# CC2340R5 register map
File version: 1.0
CPU: CM0P 1.0, other endian, MPU, FPU, 3 interrupt priority bits
Registers are 32-bit, read-write, reset 0x0 unless marked. A register's access mark holds for its fields unless they carry their own. Offsets are from the block's base; [hi:lo] are bit positions; {n}, {i} and the like mark numbered series; 'fields as' and 'values as' point back to an identical list.

## AES — The AES-128 crypto peripheral accellerates AES-128 block cipher encryption (ECB). The peripheral does also offer hardware features to accellerate cipher modes implemented in software: * CBC-MAC * CBC * CTR * CFB * OFB * PCBC The module provides two data registers that can be input to ECB encryption. These are termed TXT and BUF. TXT is the AES-128 work buffer, and content changes during an ECB encryption. Software cannot update TXT during encryption. BUF is an auxiliary 128-bit buffer with multiple purposes: * initialization vector(IV) storage * counter in CTR cipher mode * hold next value of TXT Software can update BUF during an ECB enryption. This allows software to write next TXT during an encryption an hence save ECB idle times.
Base 0x400C0000
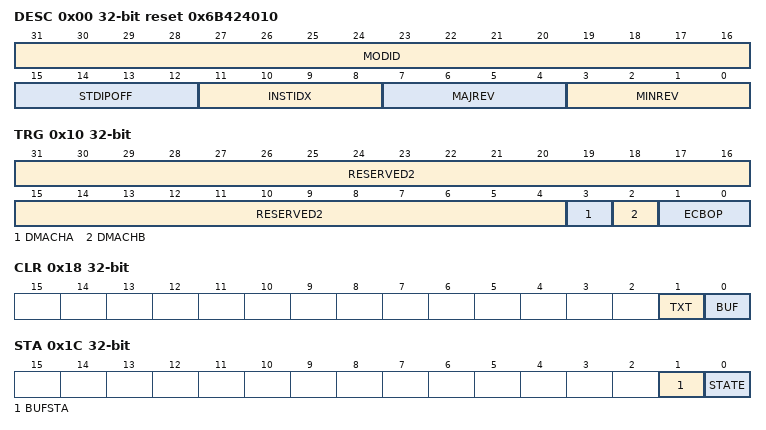
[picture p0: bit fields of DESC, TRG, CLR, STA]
0x00 DESC reset 0x6B424010 — Description Register. This register provides IP module ID, revision information, instance index and standard MMR registers offset.
  [31:16] MODID ro — [31:16] Module identifier used to uniquely identify this IP
  [15:12] STDIPOFF ro — [15:12] Standard IP MMR block offset. Standard IP MMRs are the set of from aggregated IRQ registers till DTB. 0: Standard IP MMRs do not exist 0x1-0xF: Standard IP MMRs begin at offset of (64*STDIPOFF from the base IP address)
  [11:8] INSTIDX ro — [11:8] IP Instance ID number. If multiple instances of IP exist in the device, this field can identify the instance number (0-15).
  [7:4] MAJREV ro — [7:4] Major revision of IP (0-15).
  [3:0] MINREV ro — [3:0] Minor Revision of IP(0-15).
0x10 TRG — Trigger Use this register to manually trigger operations.
  [31:4] RESERVED2 wo — [31:4] Reads to this field return zero, writes to this field are ignored.
  [3] DMACHA wo — [3:3] Write 1 to this field to manually trigger channel A request.
  [2] DMACHB wo — [2:2] Write 1 to this field to manually trigger channel B request.
  [1:0] ECBOP wo — [1:0] Electronic Codebook (ECB) Operation Write an enumerated value to this field when STA.STATE = IDLE to manually trigger an ECB encryption. If condition is not met, the trigger is ignored. Non-enumerated values are ignored. Enumerated value indicates source of ECB operation
    3=TXTXBUF (TXT = ECB(KEY, TXT XOR BUF)); 2=BUF (TXT = ECB(KEY,BUF)); 1=TXT (TXT = ECB(KEY,TXT))
0x14 ABORT — Abort Use this register to abort current ECB encryption.
  [0] ECB wo — [0:0] Electronic Codebook Write 1 to this field to abort an ongoing ECB encryption. An abort will clear TXT, BUF, DMA, AUTOCFG registers
0x18 CLR — Clear Use this register to clear contents of TXT and BUF when STA.STATE = IDLE. If condition is not met, the contents remain unchanged.
  [1] TXT wo — [1:1] Write 1 to this field to clear TXT.
  [0] BUF wo — [0:0] Write 1 to this field to clear BUF.
0x1C STA — Status This register provides information on ECB accellerator state and BUF status.
  [1] BUFSTA ro — [1:1] BUF Status Field gives the status of BUF, indicating EMPTY or FULL, when AUTOCFG.TRGECB = WRBUF3. If AUTOCFG.TRGECB != WRBUF3, then STA.BUFSTA will hold the value 0. Note : Useful for CBC-MAC
    1=FULL (Data stored in BUF is not yet consumed by the AES engine. Next block of data cannot be written into BUF until STA.STATE = IDLE.); 0=EMPTY (Data stored in BUF is already consumed by the AES engine and next block of data can be written in BUF)
  [0] STATE ro — [0:0] State Field gives the state of the ECB encryption engine.
    1=BUSY (ECB encryption active.); 0=IDLE (ECB is IDLE.)
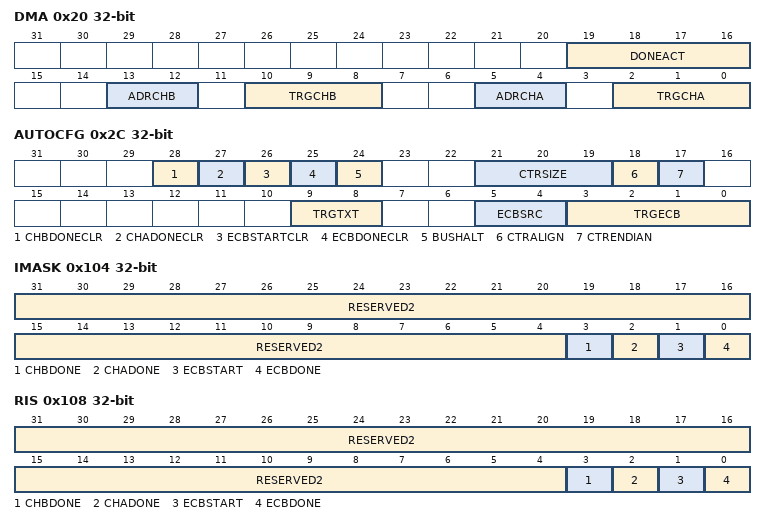
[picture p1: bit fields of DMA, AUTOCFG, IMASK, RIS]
0x20 DMA — Direct Memory Access This register controls the conditions that will generate burst requests on each DMA channel.
  [19:16] DONEACT — [19:16] Done Action This field determines the side effects of DMA done. It is allowed to configure this field with an OR-combination of supported enums, with the exception that GATE_TRGECB_ON_CHA and GATE_TRGECB_ON_CHA_DEL shall be mutually exclusive
    8=CLR_TXT_ON_CHB (DMA channel B done event clears TXT0 thru TXT3 if STA.STATE = IDLE. Event is ignored if condition is not met.); 4=CLR_TXT_ON_CHA (DMA channel A done event clears TXT0 thru TXT3 if STA.STATE = IDLE. Event is ignored if condition is not met.); 2=GATE_TRGECB_ON_CHA_DEL (Due to the pipelining of BUF writes, in certain modes, DMA CHA Done appears before the last but one ECB has completed. Setting this bit, will gate the triggers defined in AUTOCFG.TRGECB only after the last write by CHA is consumed by AES FSM. Used in ECB,CBC,CBC-MAC modes (having multiple blocks encryption) to avoid spurious ECB triggered on last read by CHB. For single mode encryption, DMA.GATE_TRGECB_ON_CHA should be used.); 1=GATE_TRGECB_ON_CHA (Triggers defined in AUTOCFG.TRGECB are gated when RIS.CHADONE = SET.); 0=DIS (DMA done has no side effect.)
  [13:12] ADRCHB — [13:12] Channel B Read Write Address The DMA accesses DMACHB to read or write contents of TXT and BUF as a response to a burst request. This field specifes the start address of the first DMA transfer that follows the burst request. The internal address gets incremented automatically for subsequent accesses. The DMA shall transfer 8-bit, 16-bit, or 32-bit words, and shall always complete a 16-byte transfer before re-arbitration.
    3=TXTXBUF0 (Start address is TXTXBUF0.); 2=BUF0 (Start address is BUF0.); 1=TXTX0 (Start address is TXTX0.); 0=TXT0 (Start address is TXT0.)
  [10:8] TRGCHB — [10:8] Channel B Trigger Select the condition that triggers DMA channel B request. Non-enumerated values are not supported and ignored.
    4=RDTXT3 (Reads of TXT3, or TXTXBUF3 trigger request.); 3=WRTXT3 (Writes to TXT3, TXTX3, or TXTXBUF3 trigger request.); 2=ECBDONE (Completion of ECB encryption triggers request.); 1=ECBSTART (Start of ECB encryption triggers request.); 0=DIS (DMA requests are disabled.)
  [5:4] ADRCHA — [5:4] Channel A Read Write Address The DMA accesses DMACHA to read or write contents of TXT and BUF as a response to a burst request. This field specifes the start address of the first DMA transfer that follows the burst request. The internal address gets incremented automatically for subsequent accesses. The DMA shall transfer 8-bit, 16-bit, or 32-bit words, and shall always complete a 16-byte transfer before re-arbitration.
    values as ADRCHB
  [2:0] TRGCHA — [2:0] Channel A Trigger Select the condition that triggers DMA channel A request. Non-enumerated values are not supported and ignored.
    4=RDTXT3 (Reads of TXT3 or TXTXBUF3 trigger request.); 3=WRTXT3 (Writes to TXT3 or TXTX3 trigger request.); 2=ECBDONE (Completion of ECB encryption triggers request.); 1=ECBSTART (Start of ECB encryption triggers request.); 0=DIS (DMA requests are disabled.)
0x24 DMACHA — DMA Channel A data transfer DMA accesses this register to read or write contents from sequential addresses specifed by DMA.ADRCHA.
  [31:0] VAL — [31:0] Value transferred through DMA Channel A
0x28 DMACHB — DMA Channel B data transfer DMA accesses this register to read or write contents from sequential addresses specifed by DMA.ADRCHB.
  [31:0] VAL — [31:0] Value transferred through DMA Channel B
0x2C AUTOCFG — Automatic Configuration This register configures automatic hardware updates to TXT and BUF. Configure this register to reduce software overhead during cipher modes.
  [28] CHBDONECLR — [28:28] This field enable auto-clear of RIS.CHBDONE interrupt on read/write of TXT3/BUF3/TXTX3/TXTXBUF3 .
    1=EN (Enable auto-clear of RIS.CHBDONE interrupt); 0=DIS (Disable auto-clear of RIS.CHBDONE interrupt)
  [27] CHADONECLR — [27:27] This field enables auto-clear of RIS.CHADONE interrupt on read/write of TXT3/BUF3/TXTX3/TXTXBUF3 .
    1=EN (Enable auto-clear of RIS.CHADONE interrupt); 0=DIS (Disable auto-clear of RIS.CHADONE interrupt)
  [26] ECBSTARTCLR — [26:26] This field enables auto-clear of RIS.ECBSTART interrupt on read/write of TXT3/BUF3/TXTX3/TXTXBUF3 .
    1=EN (Enable auto-clear of RIS.ECBSTART interrupt); 0=DIS (Disable auto-clear of RIS.ECBSTART interrupt)
  [25] ECBDONECLR — [25:25] This field enables auto-clear of RIS.ECBDONE interrupt on read/write of TXT3/BUF3/TXTX3/TXTXBUF3 .
    1=EN (Enable auto-clear of RIS.ECBDONE interrupt); 0=DIS (Disable auto-clear of RIS.ECBDONE interrupt)
  [24] BUSHALT — [24:24] Bus Halt This field decides if bus halts on access to KEY, TXT, BUF, TXTX and TXTXBUF when STA.STATE = BUSY.
    1=EN (Enable bus halt When STA.STATE = BUSY, access to KEY, TXT, TXTX, TXTXBUF halt the bus until STA.STATE = IDLE. When STA.STATE = BUSY and if either STA.BUFSTA = FULL or AUTOCFG.CTRSIZE != DISABLE, access to BUF halts the bus until STA.STATE = IDLE.); 0=DIS (Disable bus halt When STA.STATE = BUSY, writes to KEY, TXT, TXTX are ignored, reads from TXT, TXTXBUF return zero. When STA.STATE = BUSY and if either STA.BUFSTA = FULL or AUTOCFG.CTRSIZE != DISABLE, writes to BUF are ignored, reads return zero.)
  [21:19] CTRSIZE — [21:19] Counter Size Configures size of counter as either 8,16,32,64 or 128 Non-enumerated values are not supported and ignored
    5=CTR128 (Configures counter size as 128 bit); 4=CTR64 (Configures counter size as 64 bit); 3=CTR32 (Configures counter size as 32 bit); 2=CTR16 (Configures counter size as 16 bit); 1=CTR8 (Configures counter size as 8 bit); 0=DIS (Disable CTR operation)
  [18] CTRALIGN — [18:18] Counter Alignment Specifies alignment of counter
    1=RIGHTALIGN (Indicates right aligned counter Not applicable when counter size is 128bit For 128 bit counter, all octets will be considered If right aligned, octet 8-15 will be considered based on endianness and counter size); 0=LEFTALIGN (Indicates Left Aligned Counter Not applicable for 128 bit counter size. For 128 bit counter, all octets will be considered When left aligned,,octet 0-7 will be considered , based on counter size and endianness)
  [17] CTRENDIAN — [17:17] Counter Endianness Specifies Endianness of counter
    1=BIGENDIAN (Specifies Big Endian Counter Carry will flow from octet 'n' to octet 'n-1'); 0=LITTLEENDIAN (Specifies Little Endian Counter. Carry will flow from octet 'n' to octet 'n+1')
  [9:8] TRGTXT — [9:8] Trigger for TXT This field determines if and when hardware automatically XORs BUF into TXT. Non-enumerated values are not supported and ignored. It is allowed to configure this field with an OR-combination of supported enums.
    2=RDTXTXBUF3 (Hardware XORs content of BUF into TXT upon read of TXTXBUF3.); 1=RDTXT3 (Hardware XORs content of BUF into TXT upon read of TXT3.); 0=DIS (No hardware update of TXT)
  [5:4] ECBSRC — [5:4] Electronic Codebook Source This field specifies the data source to hardware-triggered ECB encryptions. Non-enumerated values are not supported and ignored.
    values as TRG.ECBOP
  [3:0] TRGECB — [3:0] Trigger Electronic Codebook This field specifies one or more actions that indirectly trigger ECB operation It is allowed to configure this field with an OR-combination of supported enums.
    8=WRBUF3S (Write to BUF3 shall schedule to trigger single action once STA.STATE is or becomes IDLE. Subsequent writes do not trigger any action unless this setting is written again to this field.); 4=WRBUF3 (All writes to BUF3 shall be scheduled to trigger action once STA.STATE is or becomes IDLE, only when AUTOCFG.CTRSIZE = DIS.); 2=RDTXT3 (All reads of TXT3 or TXTXBUF3 trigger action, only when STA.STATE = IDLE.); 1=WRTXT3 (All writes to TXT3 or TXTX3 trigger action, only when STA.STATE = IDLE.); 0=DIS (No user action indirectly triggers ECB.)
0x50 KEY0 — Key Word 0 Write KEY0 through KEY3 to populate the 128-bit key. The key is not consumed by the hardware. It is hence not required to reload the key for subsequent block encryptions unless required by the application.
  [31:0] VAL wo — [31:0] Value of KEY[31:0].
{0x50+4i} KEY{i} (i=1..3) — Key Word {i} Write KEY0 through KEY3 to populate the 128-bit key. The key is not consumed by the hardware. It is hence not required to reload the key for subsequent block encryptions unless required by the application.
  [31:0] VAL wo — [31:0] Value of KEY[{32i+31}:{32i}]
{0x70+4i} TXT{i} (i=0..2) — Text Word {i} TXT is the 128-bit buffer, the AES-128 encryption algorithm performs its operations on. ECB input can be written to TXT, and ciphertext can be read from TXT.
  [31:0] VAL — [31:0] Value of TXT[{32i+31}:{32i}]
0x7C TXT3 — Text Word 3 TXT is the 128-bit buffer, the AES-128 encryption algorithm performs its operations on. ECB input can be written to TXT, and ciphertext can be read from TXT.
  [31:0] VAL — [31:0] Value of TXT[127:96] AUTOCFG.TRGECB decides if a write to or a read of this field triggers an encryption.
{0x80+4i} TXTX{i} (i=0..2) — Text Word {i} XOR Write data to this register to XOR data with contents in TXT{i}.VAL.
  [31:0] VAL wo — [31:0] Value in TXT{i} will be TXT{i}.VAL = VAL XOR TXT{i}.VAL
0x8C TXTX3 — Text Word 3 XOR Write data to this register to XOR data with contents in TXT3.VAL. AUTOCFG.TRGECB decides if a write to or a read of this field triggers an encryption.
  [31:0] VAL wo — [31:0] Value in TXT3 will be TXT3.VAL = VAL XOR TXT3.VAL
{0x90+4i} BUF{i} (i=0..2) — Buffer Word {i} BUF is a 128-bit auxiliary register that functions as a buffer, counter, or storage of operations in cipher modes.
  [31:0] VAL — [31:0] Value of BUF[{32i+31}:{32i}]
0x9C BUF3 — Buffer Word 3 BUF is a 128-bit auxiliary register that functions as a buffer, counter, or storage of operations in cipher modes. AUTOCFG.TRGECB decides if a write to this field triggers an encryption.
  [31:0] VAL — [31:0] Value of BUF[127:96]
{0xA0+4i} TXTXBUF{i} (i=0..2) — Text Word {i} XOR Buffer Word {i} Read this register to obtain plaintext during CFB decryption.
  [31:0] VAL ro — [31:0] Value read will be TXT{i}.VAL XOR BUF{i}.VAL
0xAC TXTXBUF3 — Text Word 3 XOR Buffer Word3 Read this register to obtain plaintext during CFB decryption.
  [31:0] VAL ro — [31:0] Value read will be TXT3.VAL XOR BUF3.VAL
0x104 IMASK — Interrupt mask. This register selects interrupt sources which are allowed to pass from RIS to MIS when the corresponding bit-fields are set to 1.
  [31:4] RESERVED2 — [31:4] Reads to this field return zero, writes to this field are ignored.
  [3] CHBDONE — [3:3] DMA Channel B Done interrupt mask
    1=EN (Enable interrupt mask); 0=DIS (Disable interrupt mask)
  [2] CHADONE — [2:2] DMA Channel A Done interrupt mask
    1=EN (Enable interrupt mask); 0=DIS (Disable interrupt mask)
  [1] ECBSTART — [1:1] ECB Start interrupt mask
    1=EN (Enable interrupt mask); 0=DIS (Disable interrupt mask)
  [0] ECBDONE — [0:0] ECB Done interrupt mask
    1=EN (Enable interrupt mask); 0=DIS (Disable interrupt mask)
0x108 RIS — Raw interrupt status. This register reflects the state of all pending interrupts, regardless of masking. This register allows the user to implement a poll scheme. A flag set in this register can be cleared by writing 1 to the corresponding ICLR register bit.
  [31:4] RESERVED2 ro — [31:4] Reads to this field return zero, writes to this field are ignored.
  [3] CHBDONE ro — [3:3] Raw interrupt status for DMA Channel B Done
    1=SET (Interrupt occurred); 0=CLR (Interrupt did not occur)
  [2] CHADONE ro — [2:2] Raw interrupt status for DMA Channel A Done
    1=SET (Interrupt occurred); 0=CLR (Interrupt did not occur)
  [1] ECBSTART ro — [1:1] Raw interrupt status for ECB Start
    1=SET (Interrupt occurred); 0=CLR (Interrupt did not occur)
  [0] ECBDONE ro — [0:0] Raw interrupt status for ECB Done
    1=SET (Interrupt occurred); 0=CLR (Interrupt did not occur)
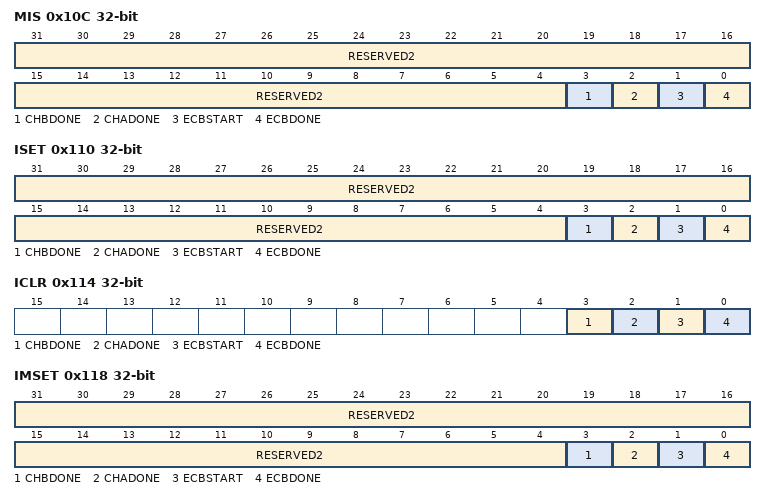
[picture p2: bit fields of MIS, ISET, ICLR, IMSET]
0x10C MIS — Masked interrupt status. This register is simply a bitwise AND of the contents of IMASK and RIS.*] registers. A flag set in this register can be cleared by writing 1 to the corresponding ICLR register bit.
  [31:4] RESERVED2 ro — [31:4] Reads to this field return zero, writes to this field are ignored.
  [3] CHBDONE ro — [3:3] Masked interrupt status for DMA Channel B Done
    1=SET (Interrupt occurred); 0=CLR (Interrupt did not occur)
  [2] CHADONE ro — [2:2] Masked interrupt status for DMA Channel A Done
    1=SET (Interrupt occurred); 0=CLR (Interrupt did not occur)
  [1] ECBSTART ro — [1:1] Masked interrupt status for ECB Start
    1=SET (Interrupt occurred); 0=CLR (Interrupt did not occur)
  [0] ECBDONE ro — [0:0] Masked interrupt status for ECB Done
    1=SET (Interrupt occurred); 0=CLR (Interrupt did not occur)
0x110 ISET — Interrupt set register. This register can used by software for diagnostics and safety checking purposes. Writing a 1 to a bit in this register will set the event and the corresponding RIS bit also gets set. If the corresponding IMASK bit is set, then the corresponding MIS register bit also gets set.
  [31:4] RESERVED2 wo — [31:4] Reads to this field return zero, writes to this field are ignored.
  [3] CHBDONE wo — [3:3] Set DMA Channel B Done interrupt
    1=SET (Set interrupt); 0=NOEFF (Writing 0 has no effect)
  [2] CHADONE wo — [2:2] Set DMA Channel A Done interrupt
    1=SET (Set interrupt); 0=NOEFF (Writing 0 has no effect)
  [1] ECBSTART wo — [1:1] Set ECB Start interrupt
    1=SET (Set interrupt); 0=NOEFF (Writing 0 has no effect)
  [0] ECBDONE wo — [0:0] Set ECB Done interrupt
    1=SET (Set interrupt); 0=NOEFF (Writing 0 has no effect)
0x114 ICLR — Interrupt clear register. This register allows software to clear interrupts. Writing a 1 to a bit in this register will clear the event and the corresponding RIS bit also gets cleared. If the corresponding IMASK bit is set, then the corresponding MIS register bit also gets cleared.
  [3] CHBDONE wo — [3:3] Clear DMA Channel B Done interrupt
    1=CLR (Clear interrupt); 0=NOEFF (Writing 0 has no effect)
  [2] CHADONE wo — [2:2] Clear DMA Channel A Done interrupt
    1=CLR (Clear interrupt); 0=NOEFF (Writing 0 has no effect)
  [1] ECBSTART wo — [1:1] Clear ECB Start interrupt
    1=CLR (Clear interrupt); 0=NOEFF (Writing 0 has no effect)
  [0] ECBDONE wo — [0:0] Clear ECB Done interrupt
    1=CLR (Clear interrupt); 0=NOEFF
0x118 IMSET — Interrupt mask set register. Writing a 1 to a bit in this register will set the corresponding IMASK bit.
  [31:4] RESERVED2 wo — [31:4] Reads to this field return zero, writes to this field are ignored.
  [3] CHBDONE wo — [3:3] Set DMA Channel B Done interrupt mask
    1=SET (Set interrupt mask); 0=NOEFF (Writing 0 has no effect)
  [2] CHADONE wo — [2:2] Set DMA Channel A Done interrupt mask
    values as CHBDONE
  [1] ECBSTART wo — [1:1] Set ECB Start interrupt mask
    values as CHBDONE
  [0] ECBDONE wo — [0:0] Set ECB Done interrupt mask
    values as CHBDONE
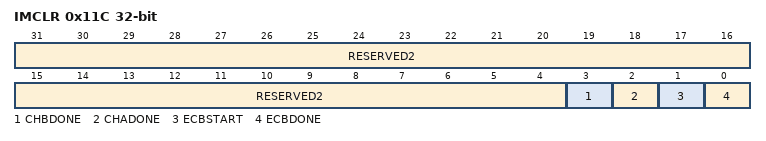
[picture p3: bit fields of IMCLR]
0x11C IMCLR — Interrupt mask clear register. Writing a 1 to a bit in this register will clear the corresponding IMASK bit.
  [31:4] RESERVED2 wo — [31:4] Reads to this field return zero, writes to this field are ignored.
  [3] CHBDONE wo — [3:3] Clear DMA Channel B Done interrupt mask
    1=CLR (Clear interrupt mask); 0=NOEFF (Writing 0 has no effect)
  [2] CHADONE wo — [2:2] Clear DMA Channel A Done interrupt mask
    values as CHBDONE
  [1] ECBSTART wo — [1:1] Clear ECB Start interrupt mask
    values as CHBDONE
  [0] ECBDONE wo — [0:0] Clear ECB Done interrupt mask
    values as CHBDONE
